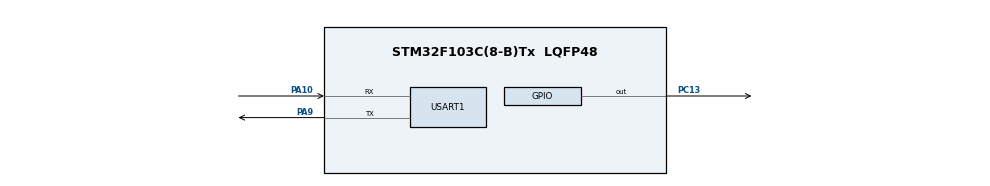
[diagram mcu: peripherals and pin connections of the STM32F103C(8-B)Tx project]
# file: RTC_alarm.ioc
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Mcu.Family=STM32F1
Mcu.Name=STM32F103C(8-B)Tx
Mcu.Package=LQFP48
NVIC.PriorityGroup=NVIC_PRIORITYGROUP_4
NVIC.RTC_Alarm_IRQn=true\:0\:0\:false\:false\:true\:true\:true
PA10.Mode=Asynchronous
PA10.Signal=USART1_RX
PA13.Mode=Serial_Wire
PA13.Signal=SYS_JTMS-SWDIO
PA14.Mode=Serial_Wire
PA14.Signal=SYS_JTCK-SWCLK
PA9.Mode=Asynchronous
PA9.Signal=USART1_TX
PC13-TAMPER-RTC.Signal=GPIO_Output
PC14-OSC32_IN.Mode=LSE-External-Oscillator
PC14-OSC32_IN.Signal=RCC_OSC32_IN
PC15-OSC32_OUT.Mode=LSE-External-Oscillator
PC15-OSC32_OUT.Signal=RCC_OSC32_OUT
PD0-OSC_IN.Mode=HSE-External-Oscillator
PD0-OSC_IN.Signal=RCC_OSC_IN
PD1-OSC_OUT.Mode=HSE-External-Oscillator
PD1-OSC_OUT.Signal=RCC_OSC_OUT
ProjectManager.HeapSize=0x200
ProjectManager.StackSize=0x400
ProjectManager.TargetToolchain=MDK-ARM V5.27
RCC.AHBFreq_Value=72000000
RCC.APB1CLKDivider=RCC_HCLK_DIV2
RCC.APB1Freq_Value=36000000
RCC.APB1TimFreq_Value=72000000
RCC.APB2Freq_Value=72000000
RCC.APB2TimFreq_Value=72000000
RCC.HCLKFreq_Value=72000000
RCC.PLLMUL=RCC_PLL_MUL9
RCC.PLLSourceVirtual=RCC_PLLSOURCE_HSE
RCC.RTCClockSelection=RCC_RTCCLKSOURCE_LSE
RCC.SYSCLKFreq_VALUE=72000000
RCC.SYSCLKSource=RCC_SYSCLKSOURCE_PLLCLK
RCC.USBFreq_Value=72000000
USART1.VirtualMode=VM_ASYNC
VP_RTC_VS_RTC_Activate.Mode=RTC_Enabled
VP_RTC_VS_RTC_Calendar.Mode=RTC_Calendar
board=custom

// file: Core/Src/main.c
/* USER CODE BEGIN Header */
/**
  ******************************************************************************
  * @file           : main.c
  * @brief          : Main program body
  ******************************************************************************
  * @attention
  *
  * <h2><center>&copy; Copyright (c) 2021 STMicroelectronics.
  * All rights reserved.</center></h2>
  *
  * This software component is licensed by ST under BSD 3-Clause license,
  * the "License"; You may not use this file except in compliance with the
  * License. You may obtain a copy of the License at:
  *                        opensource.org/licenses/BSD-3-Clause
  *
  ******************************************************************************
  */
/* USER CODE END Header */
#include "main.h"

/* USER CODE BEGIN Includes */
#include "stdio.h"
/* USER CODE END Includes */

void SystemClock_Config(void);
static void MX_GPIO_Init(void);
static void MX_RTC_Init(void);
static void MX_USART1_UART_Init(void);

/* USER CODE BEGIN 0 */
	/* Function for transmitting 8bit data via USART */
	void write_uart(char data)
	{
		while(!LL_USART_IsActiveFlag_TXE(USART1));
		LL_USART_TransmitData8(USART1, (uint8_t)data);
	}

	/* Retargeting stdout_putchar as to use USART_TX for data output */
	int stdout_putchar (int ch) {
	  write_uart(ch);
	  return (ch);
	}

////////////////////////
struct time_t
{
  uint8_t sec;
  uint8_t min;
  uint8_t hour;
};

struct time_t Time;
struct time_t Alarm;

struct date_t
{
  uint8_t month;
  uint8_t day;
  uint16_t year;
};
struct date_t Date;

uint8_t EndOfMonth[12]= {31, 28, 31, 30, 31, 30, 31, 31, 30, 31, 30, 31};
uint32_t TimeCounter = 0;

void DATE_Update(void);
void TIME_Update(void);
void DATE_Config(uint8_t, uint8_t, uint16_t);
void TIME_Config(uint8_t, uint8_t, uint8_t);
void ALARM_Config(uint8_t, uint8_t, uint8_t);
/* USER CODE END 0 */

int main(void)
{

  /* MCU Configuration--------------------------------------------------------*/

  /* Reset of all peripherals, Initializes the Flash interface and the Systick. */

  LL_APB2_GRP1_EnableClock(LL_APB2_GRP1_PERIPH_AFIO);
  LL_APB1_GRP1_EnableClock(LL_APB1_GRP1_PERIPH_PWR);

  NVIC_SetPriorityGrouping(NVIC_PRIORITYGROUP_4);

  /* System interrupt init*/

  /** NOJTAG: JTAG-DP Disabled and SW-DP Enabled
  */
  LL_GPIO_AF_Remap_SWJ_NOJTAG();

  /* Configure the system clock */
  SystemClock_Config();

  /* Initialize all configured peripherals */
  MX_GPIO_Init();
  MX_RTC_Init();
  MX_USART1_UART_Init();
  /* USER CODE BEGIN 2 */
  /* configue date, time and alarm and also enabling alarm interrupt */
  LL_RTC_DisableWriteProtection(RTC);
  LL_RTC_EnterInitMode(RTC);

	DATE_Config(12, 13, 2021);
	TIME_Config(23, 59, 57);
	ALARM_Config(12, 00, 05);
	LL_RTC_EnableIT_ALR(RTC);
	LL_EXTI_EnableIT_0_31(LL_EXTI_LINE_17);
	LL_EXTI_EnableRisingTrig_0_31(LL_EXTI_LINE_17);

	LL_RTC_ExitInitMode(RTC);
	LL_RTC_EnableWriteProtection(RTC);
  /* USER CODE END 2 */

  /* Infinite loop */
  while (1)
  {

    /* USER CODE BEGIN 3 */
		/* update and print date and time */
		for(int i=0; i<10; i++)
		{
		TIME_Update();
		DATE_Update();
		printf("Time: %.2d:%.2d:%.2d\r\n", Time.hour, Time.min, Time.sec);
		LL_mDelay(998);
		}
		printf("Date: %.2d/%.2d/%.4d\r\n", Date.month, Date.day, Date.year);
  }
  /* USER CODE END 3 */
}

void SystemClock_Config(void)
{
  LL_FLASH_SetLatency(LL_FLASH_LATENCY_2);
  while(LL_FLASH_GetLatency()!= LL_FLASH_LATENCY_2)
  {
  }
  LL_RCC_HSE_Enable();

   /* Wait till HSE is ready */
  while(LL_RCC_HSE_IsReady() != 1)
  {

  }
  LL_PWR_EnableBkUpAccess();
  LL_RCC_LSE_Enable();

   /* Wait till LSE is ready */
  while(LL_RCC_LSE_IsReady() != 1)
  {

  }
  if(LL_RCC_GetRTCClockSource() != LL_RCC_RTC_CLKSOURCE_LSE)
  {
    LL_RCC_ForceBackupDomainReset();
    LL_RCC_ReleaseBackupDomainReset();
    LL_RCC_SetRTCClockSource(LL_RCC_RTC_CLKSOURCE_LSE);
  }
  LL_RCC_EnableRTC();
  LL_RCC_PLL_ConfigDomain_SYS(LL_RCC_PLLSOURCE_HSE_DIV_1, LL_RCC_PLL_MUL_9);
  LL_RCC_PLL_Enable();

   /* Wait till PLL is ready */
  while(LL_RCC_PLL_IsReady() != 1)
  {

  }
  LL_RCC_SetAHBPrescaler(LL_RCC_SYSCLK_DIV_1);
  LL_RCC_SetAPB1Prescaler(LL_RCC_APB1_DIV_2);
  LL_RCC_SetAPB2Prescaler(LL_RCC_APB2_DIV_1);
  LL_RCC_SetSysClkSource(LL_RCC_SYS_CLKSOURCE_PLL);

   /* Wait till System clock is ready */
  while(LL_RCC_GetSysClkSource() != LL_RCC_SYS_CLKSOURCE_STATUS_PLL)
  {

  }
  LL_Init1msTick(72000000);
  LL_SetSystemCoreClock(72000000);
}

static void MX_RTC_Init(void)
{

  LL_RTC_InitTypeDef RTC_InitStruct = {0};
  LL_RTC_TimeTypeDef RTC_TimeStruct = {0};

    LL_PWR_EnableBkUpAccess();
    /* Enable BKP CLK enable for backup registers */
    LL_APB1_GRP1_EnableClock(LL_APB1_GRP1_PERIPH_BKP);
  /* Peripheral clock enable */
  LL_RCC_EnableRTC();

  /* RTC interrupt Init */
  NVIC_SetPriority(RTC_Alarm_IRQn, NVIC_EncodePriority(NVIC_GetPriorityGrouping(),0, 0));
  NVIC_EnableIRQ(RTC_Alarm_IRQn);

  /** Initialize RTC and set the Time and Date
  */
  RTC_InitStruct.AsynchPrescaler = 0xFFFFFFFFU;
  LL_RTC_Init(RTC, &RTC_InitStruct);
  LL_RTC_SetAsynchPrescaler(RTC, 0xFFFFFFFFU);
  /** Initialize RTC and set the Time and Date
  */
  RTC_TimeStruct.Hours = 0;
  RTC_TimeStruct.Minutes = 0;
  RTC_TimeStruct.Seconds = 0;
  LL_RTC_TIME_Init(RTC, LL_RTC_FORMAT_BCD, &RTC_TimeStruct);
  /* USER CODE BEGIN RTC_Init 2 */
  /* set RTC clock prescaler to 32768 (8000 hex)*/
  RTC_InitStruct.AsynchPrescaler = 0x00008000U;
  LL_RTC_Init(RTC, &RTC_InitStruct);
  LL_RTC_SetAsynchPrescaler(RTC, 0x00008000U);
  /* USER CODE END RTC_Init 2 */

}

static void MX_USART1_UART_Init(void)
{

  LL_USART_InitTypeDef USART_InitStruct = {0};

  LL_GPIO_InitTypeDef GPIO_InitStruct = {0};

  /* Peripheral clock enable */
  LL_APB2_GRP1_EnableClock(LL_APB2_GRP1_PERIPH_USART1);

  LL_APB2_GRP1_EnableClock(LL_APB2_GRP1_PERIPH_GPIOA);
  /**USART1 GPIO Configuration
  PA9   ------> USART1_TX
  PA10   ------> USART1_RX
  */
  GPIO_InitStruct.Pin = LL_GPIO_PIN_9;
  GPIO_InitStruct.Mode = LL_GPIO_MODE_ALTERNATE;
  GPIO_InitStruct.Speed = LL_GPIO_SPEED_FREQ_HIGH;
  GPIO_InitStruct.OutputType = LL_GPIO_OUTPUT_PUSHPULL;
  LL_GPIO_Init(GPIOA, &GPIO_InitStruct);

  GPIO_InitStruct.Pin = LL_GPIO_PIN_10;
  GPIO_InitStruct.Mode = LL_GPIO_MODE_FLOATING;
  LL_GPIO_Init(GPIOA, &GPIO_InitStruct);

  USART_InitStruct.BaudRate = 115200;
  USART_InitStruct.DataWidth = LL_USART_DATAWIDTH_8B;
  USART_InitStruct.StopBits = LL_USART_STOPBITS_1;
  USART_InitStruct.Parity = LL_USART_PARITY_NONE;
  USART_InitStruct.TransferDirection = LL_USART_DIRECTION_TX_RX;
  USART_InitStruct.HardwareFlowControl = LL_USART_HWCONTROL_NONE;
  USART_InitStruct.OverSampling = LL_USART_OVERSAMPLING_16;
  LL_USART_Init(USART1, &USART_InitStruct);
  LL_USART_ConfigAsyncMode(USART1);
  LL_USART_Enable(USART1);

}

static void MX_GPIO_Init(void)
{
  LL_GPIO_InitTypeDef GPIO_InitStruct = {0};

  /* GPIO Ports Clock Enable */
  LL_APB2_GRP1_EnableClock(LL_APB2_GRP1_PERIPH_GPIOC);
  LL_APB2_GRP1_EnableClock(LL_APB2_GRP1_PERIPH_GPIOD);
  LL_APB2_GRP1_EnableClock(LL_APB2_GRP1_PERIPH_GPIOA);

  /**/
  LL_GPIO_ResetOutputPin(GPIOC, LL_GPIO_PIN_13);

  /**/
  GPIO_InitStruct.Pin = LL_GPIO_PIN_13;
  GPIO_InitStruct.Mode = LL_GPIO_MODE_OUTPUT;
  GPIO_InitStruct.Speed = LL_GPIO_SPEED_FREQ_LOW;
  GPIO_InitStruct.OutputType = LL_GPIO_OUTPUT_PUSHPULL;
  LL_GPIO_Init(GPIOC, &GPIO_InitStruct);

}

/* USER CODE BEGIN 4 */
void DATE_Config( uint8_t fMonth,  uint8_t fDay, uint16_t fYear)
{
	Date.month = fMonth;
  Date.day   = fDay;
  Date.year  = fYear;
}

void DATE_Update(void)
{
  if ((Time.hour == 00) & (Time.min == 00) & (Time.sec == 00))
  {
    if(Date.day == EndOfMonth[Date.month -1])
    {
      Date.day = 1U;
      Date.month += 1U;
    }
    else
    {
      Date.day = Date.day + 1;
    }

		if (Date.month == 13)
		{
		Date.month = 1;
		Date.year += 1;
		}
  }

}

void TIME_Update(void)
{
  TimeCounter = LL_RTC_TIME_Get(RTC);
  Time.hour = (TimeCounter/3600) % 24;
  Time.min  = (TimeCounter % 3600) / 60;
  Time.sec  = (TimeCounter % 3600) % 60;
}

void TIME_Config(uint8_t fHour, uint8_t fMin, uint8_t fSec)
{
  Time.hour = fHour;
  Time.min  = fMin;
  Time.sec  = fSec;

  LL_RTC_TIME_Set(RTC,((Time.hour * 3600) +
                       (Time.min * 60) +
                        Time.sec));
}

void ALARM_Config(uint8_t fHour, uint8_t fMin, uint8_t fSec)
{
  Alarm.hour = fHour;
  Alarm.min  = fMin;
  Alarm.sec  = fSec;

  LL_RTC_ALARM_Set(RTC,((Alarm.hour * 3600) +
                        (Alarm.min * 60) +
                         Alarm.sec));
}
/* USER CODE END 4 */

void Error_Handler(void)
{
  __disable_irq();
  while (1)
  {
  }
}

/************************ (C) COPYRIGHT STMicroelectronics *****END OF FILE****/
